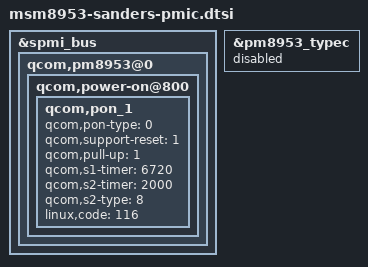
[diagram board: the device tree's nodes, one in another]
&spmi_bus {
	qcom,pm8953@0 {
		qcom,power-on@800 {
			qcom,pon_1 {
				qcom,pon-type = <0>;
				qcom,support-reset = <1>;
				qcom,pull-up = <1>;
				qcom,s1-timer = <6720>;
				qcom,s2-timer = <2000>;
				qcom,s2-type = <8>;
				linux,code = <116>;
			};
		};
	};
};

&pm8953_typec {
	status = "disabled";
};
